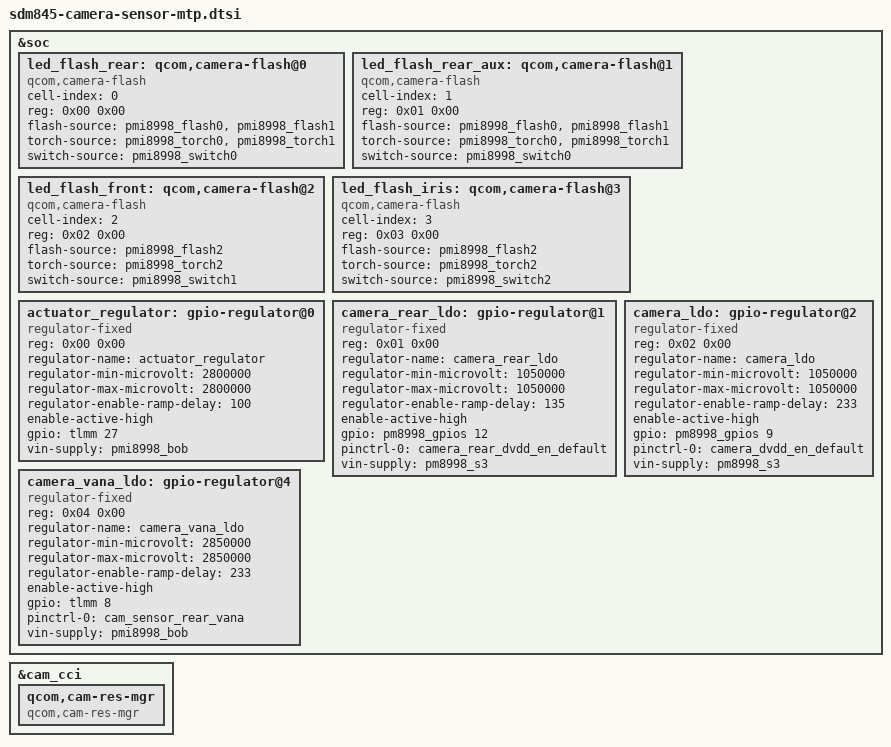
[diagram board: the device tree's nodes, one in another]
/*
 * Copyright (c) 2016-2018, The Linux Foundation. All rights reserved.
 *
 * This program is free software; you can redistribute it and/or modify
 * it under the terms of the GNU General Public License version 2 and
 * only version 2 as published by the Free Software Foundation.
 *
 * This program is distributed in the hope that it will be useful,
 * but WITHOUT ANY WARRANTY; without even the implied warranty of
 * MERCHANTABILITY or FITNESS FOR A PARTICULAR PURPOSE.  See the
 * GNU General Public License for more details.
 */

&soc {
	led_flash_rear: qcom,camera-flash@0 {
		cell-index = <0>;
		reg = <0x00 0x00>;
		compatible = "qcom,camera-flash";
		flash-source = <&pmi8998_flash0 &pmi8998_flash1>;
		torch-source = <&pmi8998_torch0 &pmi8998_torch1>;
		switch-source = <&pmi8998_switch0>;
		status = "ok";
	};

	led_flash_rear_aux: qcom,camera-flash@1 {
		cell-index = <1>;
		reg = <0x01 0x00>;
		compatible = "qcom,camera-flash";
		flash-source = <&pmi8998_flash0 &pmi8998_flash1>;
		torch-source = <&pmi8998_torch0 &pmi8998_torch1>;
		switch-source = <&pmi8998_switch0>;
		status = "ok";
	};

	led_flash_front: qcom,camera-flash@2 {
		cell-index = <2>;
		reg = <0x02 0x00>;
		compatible = "qcom,camera-flash";
		flash-source = <&pmi8998_flash2>;
		torch-source = <&pmi8998_torch2>;
		switch-source = <&pmi8998_switch1>;
		status = "ok";
	};

	led_flash_iris: qcom,camera-flash@3 {
		cell-index = <3>;
		reg = <0x03 0x00>;
		compatible = "qcom,camera-flash";
		flash-source = <&pmi8998_flash2>;
		torch-source = <&pmi8998_torch2>;
		switch-source = <&pmi8998_switch2>;
		status = "ok";
	};

	actuator_regulator: gpio-regulator@0 {
		compatible = "regulator-fixed";
		reg = <0x00 0x00>;
		regulator-name = "actuator_regulator";
		regulator-min-microvolt = <2800000>;
		regulator-max-microvolt = <2800000>;
		regulator-enable-ramp-delay = <100>;
		enable-active-high;
		gpio = <&tlmm 27 0>;
		vin-supply = <&pmi8998_bob>;
	};

	camera_rear_ldo: gpio-regulator@1 {
		compatible = "regulator-fixed";
		reg = <0x01 0x00>;
		regulator-name = "camera_rear_ldo";
		regulator-min-microvolt = <1050000>;
		regulator-max-microvolt = <1050000>;
		regulator-enable-ramp-delay = <135>;
		enable-active-high;
		gpio = <&pm8998_gpios 12 0>;
		pinctrl-names = "default";
		pinctrl-0 = <&camera_rear_dvdd_en_default>;
		vin-supply = <&pm8998_s3>;
	};

	camera_ldo: gpio-regulator@2 {
		compatible = "regulator-fixed";
		reg = <0x02 0x00>;
		regulator-name = "camera_ldo";
		regulator-min-microvolt = <1050000>;
		regulator-max-microvolt = <1050000>;
		regulator-enable-ramp-delay = <233>;
		enable-active-high;
		gpio = <&pm8998_gpios 9 0>;
		pinctrl-names = "default";
		pinctrl-0 = <&camera_dvdd_en_default>;
		vin-supply = <&pm8998_s3>;
	};

	camera_vana_ldo: gpio-regulator@4 {
		compatible = "regulator-fixed";
		reg = <0x04 0x00>;
		regulator-name = "camera_vana_ldo";
		regulator-min-microvolt = <2850000>;
		regulator-max-microvolt = <2850000>;
		regulator-enable-ramp-delay = <233>;
		enable-active-high;
		gpio = <&tlmm 8 0>;
		pinctrl-names = "default";
		pinctrl-0 = <&cam_sensor_rear_vana>;
		vin-supply = <&pmi8998_bob>;
	};
};

&cam_cci {
	qcom,cam-res-mgr {
		compatible = "qcom,cam-res-mgr";
		status = "ok";
	};
};
